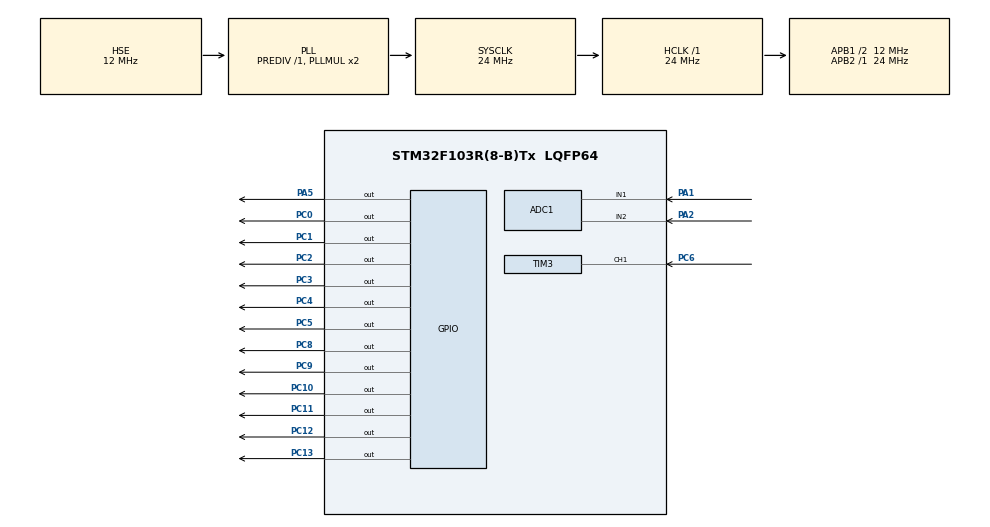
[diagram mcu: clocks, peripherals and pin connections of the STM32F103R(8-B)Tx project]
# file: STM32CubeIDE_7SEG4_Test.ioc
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ADC1.Channel-0\#ChannelRegularConversion=ADC_CHANNEL_1
ADC1.Channel-1\#ChannelRegularConversion=ADC_CHANNEL_2
ADC1.ContinuousConvMode=ENABLE
ADC1.NbrOfConversion=2
ADC1.NbrOfConversionFlag=1
ADC1.Rank-1\#ChannelRegularConversion=2
ADC1.SamplingTime-0\#ChannelRegularConversion=ADC_SAMPLETIME_71CYCLES_5
ADC1.SamplingTime-1\#ChannelRegularConversion=ADC_SAMPLETIME_71CYCLES_5
ADC1.master=1
Dma.ADC1.0.Direction=DMA_PERIPH_TO_MEMORY
Dma.ADC1.0.Instance=DMA1_Channel1
Dma.ADC1.0.MemDataAlignment=DMA_MDATAALIGN_WORD
Dma.ADC1.0.MemInc=DMA_MINC_ENABLE
Dma.ADC1.0.Mode=DMA_CIRCULAR
Dma.ADC1.0.PeriphDataAlignment=DMA_PDATAALIGN_WORD
Dma.ADC1.0.PeriphInc=DMA_PINC_DISABLE
Dma.ADC1.0.Priority=DMA_PRIORITY_LOW
Dma.Request0=ADC1
Mcu.Family=STM32F1
Mcu.Name=STM32F103R(8-B)Tx
Mcu.Package=LQFP64
NVIC.DMA1_Channel1_IRQn=true\:0\:0\:false\:false\:true\:false\:true
NVIC.PriorityGroup=NVIC_PRIORITYGROUP_4
NVIC.TIM3_IRQn=true\:0\:0\:false\:false\:true\:true\:true
PA1.Signal=ADCx_IN1
PA13.Mode=Serial_Wire
PA13.Signal=SYS_JTMS-SWDIO
PA14.Mode=Serial_Wire
PA14.Signal=SYS_JTCK-SWCLK
PA2.Signal=ADCx_IN2
PA5.Signal=GPIO_Output
PC0.Signal=GPIO_Output
PC1.Signal=GPIO_Output
PC10.Signal=GPIO_Output
PC11.Signal=GPIO_Output
PC12.Signal=GPIO_Output
PC13-TAMPER-RTC.Signal=GPIO_Output
PC2.Signal=GPIO_Output
PC3.Signal=GPIO_Output
PC4.Signal=GPIO_Output
PC5.Signal=GPIO_Output
PC6.Signal=S_TIM3_CH1
PC8.Signal=GPIO_Output
PC9.Signal=GPIO_Output
PD0-OSC_IN.Mode=HSE-External-Oscillator
PD0-OSC_IN.Signal=RCC_OSC_IN
PD1-OSC_OUT.Mode=HSE-External-Oscillator
PD1-OSC_OUT.Signal=RCC_OSC_OUT
ProjectManager.HeapSize=0x200
ProjectManager.StackSize=0x400
ProjectManager.TargetToolchain=STM32CubeIDE
RCC.AHBFreq_Value=24000000
RCC.APB1CLKDivider=RCC_HCLK_DIV2
RCC.APB1Freq_Value=12000000
RCC.APB1TimFreq_Value=24000000
RCC.APB2Freq_Value=24000000
RCC.APB2TimFreq_Value=24000000
RCC.HCLKFreq_Value=24000000
RCC.HSE_VALUE=12000000
RCC.PLLSourceVirtual=RCC_PLLSOURCE_HSE
RCC.SYSCLKFreq_VALUE=24000000
RCC.SYSCLKSource=RCC_SYSCLKSOURCE_PLLCLK
RCC.USBFreq_Value=24000000
SH.ADCx_IN1.0=ADC1_IN1,IN1
SH.ADCx_IN2.0=ADC1_IN2,IN2
SH.S_TIM3_CH1.0=TIM3_CH1,Input_Capture1_from_TI1
TIM3.Channel-Input_Capture1_from_TI1=TIM_CHANNEL_1
TIM3.Period=0xffff-1
TIM3.Prescaler=90-1
VP_TIM3_VS_ClockSourceINT.Mode=Internal
board=custom

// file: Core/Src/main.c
/* USER CODE BEGIN Header */
/**
  ******************************************************************************
  * @file           : main.c
  * @brief          : Main program body
  ******************************************************************************
  * @attention
  *
  * Copyright (c) 2023 STMicroelectronics.
  * All rights reserved.
  *
  * This software is licensed under terms that can be found in the LICENSE file
  * in the root directory of this software component.
  * If no LICENSE file comes with this software, it is provided AS-IS.
  *
  ******************************************************************************
  */
/* USER CODE END Header */
#include "main.h"
#include "adc.h"
#include "dma.h"
#include "tim.h"
#include "gpio.h"

/* USER CODE BEGIN Includes */
#include "_7_seg.h"
#define DcMotorlEnable() HAL_GPIO_WritePin(GPIO, GPIO_PIN_)
/* USER CODE END Includes */

void SystemClock_Config(void);

int main(void)
{

  /* MCU Configuration--------------------------------------------------------*/

  /* Reset of all peripherals, Initializes the Flash interface and the Systick. */
  HAL_Init();

  /* USER CODE BEGIN Init */
  uint32_t XY[2];
  /* USER CODE END Init */

  /* Configure the system clock */
  SystemClock_Config();

  /* Initialize all configured peripherals */
  MX_GPIO_Init();
  MX_TIM3_Init();
  MX_DMA_Init();
  MX_ADC1_Init();
  /* USER CODE BEGIN 2 */
  HAL_ADC_Start_DMA(&hadc1, XY, 2);	// start ADC in DMA mode for Multi channel
  /* USER CODE END 2 */

  /* Infinite loop */
  /* USER CODE BEGIN WHILE */
  while (1)
  {

	  PowerOn_7_SEG();
	  Off_7_SEG_AllPin();
	  for(int i=0; i<10; i++)
	  {
		  _7_SEG_Num_Test(i);
	  }

    /* USER CODE END WHILE */

  }
}

void SystemClock_Config(void)
{
  RCC_OscInitTypeDef RCC_OscInitStruct = {0};
  RCC_ClkInitTypeDef RCC_ClkInitStruct = {0};
  RCC_PeriphCLKInitTypeDef PeriphClkInit = {0};

  /** Initializes the RCC Oscillators according to the specified parameters
  * in the RCC_OscInitTypeDef structure.
  */
  RCC_OscInitStruct.OscillatorType = RCC_OSCILLATORTYPE_HSE;
  RCC_OscInitStruct.HSEState = RCC_HSE_ON;
  RCC_OscInitStruct.HSEPredivValue = RCC_HSE_PREDIV_DIV1;
  RCC_OscInitStruct.HSIState = RCC_HSI_ON;
  RCC_OscInitStruct.PLL.PLLState = RCC_PLL_ON;
  RCC_OscInitStruct.PLL.PLLSource = RCC_PLLSOURCE_HSE;
  RCC_OscInitStruct.PLL.PLLMUL = RCC_PLL_MUL2;
  if (HAL_RCC_OscConfig(&RCC_OscInitStruct) != HAL_OK)
  {
    Error_Handler();
  }
  /** Initializes the CPU, AHB and APB buses clocks
  */
  RCC_ClkInitStruct.ClockType = RCC_CLOCKTYPE_HCLK|RCC_CLOCKTYPE_SYSCLK
                              |RCC_CLOCKTYPE_PCLK1|RCC_CLOCKTYPE_PCLK2;
  RCC_ClkInitStruct.SYSCLKSource = RCC_SYSCLKSOURCE_PLLCLK;
  RCC_ClkInitStruct.AHBCLKDivider = RCC_SYSCLK_DIV1;
  RCC_ClkInitStruct.APB1CLKDivider = RCC_HCLK_DIV2;
  RCC_ClkInitStruct.APB2CLKDivider = RCC_HCLK_DIV1;

  if (HAL_RCC_ClockConfig(&RCC_ClkInitStruct, FLASH_LATENCY_0) != HAL_OK)
  {
    Error_Handler();
  }
  PeriphClkInit.PeriphClockSelection = RCC_PERIPHCLK_ADC;
  PeriphClkInit.AdcClockSelection = RCC_ADCPCLK2_DIV2;
  if (HAL_RCCEx_PeriphCLKConfig(&PeriphClkInit) != HAL_OK)
  {
    Error_Handler();
  }
}

void Error_Handler(void)
{
  __disable_irq();
  while (1)
  {
  }
}
